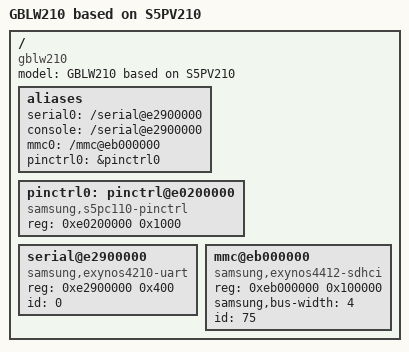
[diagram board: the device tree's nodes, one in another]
// SPDX-License-Identifier: GPL-2.0+
/*
 * Samsung's S5PC110-based Goni board device tree source
 *
 * Copyright (c) 2014 Google, Inc
 */

/dts-v1/;

#include "skeleton.dtsi"
#include "s5pc110-pinctrl.dtsi"

/ {
	model = "GBLW210 based on S5PV210";
	compatible = "gblw210", "samsung,s5pv210";

	aliases {
		serial0 = "/serial@e2900000";
		console = "/serial@e2900000";
		mmc0 = "/mmc@eb000000";
		pinctrl0 = &pinctrl0;
	};

	pinctrl0: pinctrl@e0200000 {
		compatible = "samsung,s5pc110-pinctrl";
		reg = <0xe0200000 0x1000>;
	};

	serial@e2900000 {
		compatible = "samsung,exynos4210-uart";
		reg = <0xe2900000 0x400>;
		id = <0>;
	};

	mmc@eb000000 {
		compatible = "samsung,exynos4412-sdhci";
		reg = <0xeb000000 0x100000>;
		samsung,bus-width = <4>;
		id = <75>;
		// non-removable;
		status = "okay";
	};

};
